AUTOSAR XML (schema 00046)
standard types defined: boolean, uint8, uint16, uint32, boolean_DataConstr, boolean_CompuMethod
package /PortInterfaces
  7 x sender receiver interface:
    LockCmd
      data LockCmd: type=uint8
    LockReq
      data LockReq: type=uint8
    VehSpd
      data VehSpd: type=uint16
    VehSpdVld
      data VehSpdVld: type=uint8
    FrLeDoorSts
      data FrLeDoorSts: type=uint8
    ReLeDoorSts3
      data ReLeDoorSts4: type=uint8
    ReLeDoorSts
      data ReLeDoorSts: type=uint8
  client server interface SetDoorCmd
    operation DoorMethod
      arg outvalue: type=uint8, direction=OUT, server-argument-impl-policy=USE-ARGUMENT-TYPE
      arg invalue: type=uint8, direction=IN, server-argument-impl-policy=USE-ARGUMENT-TYPE
  client server interface SetSeatCmd
    operation SeatMethod
      arg outvalue: type=uint8, direction=OUT, server-argument-impl-policy=USE-ARGUMENT-TYPE
      arg invalue: type=uint8, direction=IN, server-argument-impl-policy=USE-ARGUMENT-TYPE
  client server interface CSwindowCmd
    operation method1
      arg outvalue: type=uint8, direction=OUT, server-argument-impl-policy=USE-ARGUMENT-TYPE
      arg invalue: type=uint8, direction=IN, server-argument-impl-policy=USE-ARGUMENT-TYPE
    operation method2
      arg outvalue: type=uint8, direction=OUT, server-argument-impl-policy=USE-ARGUMENT-TYPE
      arg invalue: type=uint8, direction=IN, server-argument-impl-policy=USE-ARGUMENT-TYPE
package /Constants
  7 x constant specification, all with value-spec=0:
    LockCmd_IV
    LockReq_IV
    VehSpd_IV
    VehSpdVld_IV
    FrLeDoorSts_IV
    ReLeDoorSts4_IV
    ReLeDoorSts_IV
package /ComponentTypes
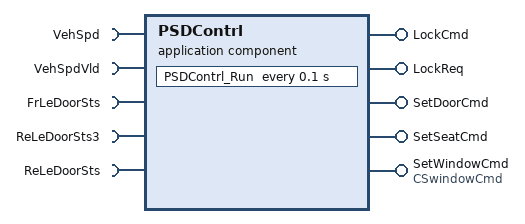
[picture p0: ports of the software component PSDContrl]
  application sw component type PSDContrl
    provide port LockCmd: nonqueued-sender-com-spec{data-element=LockCmd, init-value=constant-reference=LockCmd_IV}, provided-interface=LockCmd
    provide port LockReq: nonqueued-sender-com-spec{data-element=LockReq, init-value=constant-reference=LockReq_IV}, provided-interface=LockReq
    5 x require port:
      VehSpd: nonqueued-receiver-com-spec{data-element=VehSpd, init-value=constant-reference=VehSpd_IV}, required-interface=VehSpd
      VehSpdVld: nonqueued-receiver-com-spec{data-element=VehSpdVld, init-value=constant-reference=VehSpdVld_IV}, required-interface=VehSpdVld
      FrLeDoorSts: nonqueued-receiver-com-spec{data-element=FrLeDoorSts, init-value=constant-reference=FrLeDoorSts_IV}, required-interface=FrLeDoorSts
      ReLeDoorSts3: nonqueued-receiver-com-spec{data-element=ReLeDoorSts4, init-value=constant-reference=ReLeDoorSts4_IV}, required-interface=ReLeDoorSts3
      ReLeDoorSts: nonqueued-receiver-com-spec{data-element=ReLeDoorSts, init-value=constant-reference=ReLeDoorSts_IV}, required-interface=ReLeDoorSts
    provide port SetDoorCmd: server-com-spec=DoorMethod, provided-interface=SetDoorCmd
    provide port SetSeatCmd: server-com-spec=SeatMethod, provided-interface=SetSeatCmd
    provide port SetWindowCmd: provided-com-specs=[method1, method2], provided-interface=CSwindowCmd
    behavior PSDContrl_InternalBehavior
      exclusive area ExampleExclusiveArea
      init event IT_PSDContrl_Init: start-on-event=PSDContrl_Init
      timing event TMT_PSDContrl_Run: start-on-event=PSDContrl_Run, period=0.1
      4 x operation invoked event:
        OIT_PSDContrl_SetDoorCmd_DoorMethod_SetDoorCmd_DoorMethod: start-on-event=PSDContrl_SetDoorCmd_DoorMethod, operation=SetDoorCmd.DoorMethod
        OIT_PSDContrl_SetSeatCmd_SeatMethod_SetSeatCmd_SeatMethod: start-on-event=PSDContrl_SetSeatCmd_SeatMethod, operation=SetSeatCmd.SeatMethod
        OIT_PSDContrl_SetWindowCmd_method1_SetWindowCmd_method1: start-on-event=PSDContrl_SetWindowCmd_method1, operation=SetWindowCmd.method1
        OIT_PSDContrl_SetWindowCmd_method2_SetWindowCmd_method2: start-on-event=PSDContrl_SetWindowCmd_method2, operation=SetWindowCmd.method2
      port-api-options:
        enable-take-address=false, indirect-api=false, port=FrLeDoorSts
        enable-take-address=false, indirect-api=false, port=LockCmd
        enable-take-address=false, indirect-api=false, port=LockReq
        enable-take-address=false, indirect-api=false, port=ReLeDoorSts
        enable-take-address=false, indirect-api=false, port=ReLeDoorSts3
        enable-take-address=false, indirect-api=false, port=SetDoorCmd
        enable-take-address=false, indirect-api=false, port=SetSeatCmd
        enable-take-address=false, indirect-api=false, port=SetWindowCmd
        enable-take-address=false, indirect-api=false, port=VehSpd
        enable-take-address=false, indirect-api=false, port=VehSpdVld
      6 x runnable:
        PSDContrl_Init
        PSDContrl_Run
          data-receive-point-by-arguments:
            5 x access:
              REC_VehSpd_VehSpd: accessed-variable=VehSpd.VehSpd
              REC_VehSpdVld_VehSpdVld: accessed-variable=VehSpdVld.VehSpdVld
              REC_FrLeDoorSts_FrLeDoorSts: accessed-variable=FrLeDoorSts.FrLeDoorSts
              REC_ReLeDoorSts3_ReLeDoorSts4: accessed-variable=ReLeDoorSts3.ReLeDoorSts4
              REC_ReLeDoorSts_ReLeDoorSts: accessed-variable=ReLeDoorSts.ReLeDoorSts
          data-send-points:
            access SEND_LockCmd_LockCmd: accessed-variable=LockCmd.LockCmd
            access SEND_LockReq_LockReq: accessed-variable=LockReq.LockReq
        PSDContrl_SetDoorCmd_DoorMethod
        PSDContrl_SetSeatCmd_SeatMethod
        PSDContrl_SetWindowCmd_method1
        PSDContrl_SetWindowCmd_method2
  swc implementation PSDContrl_Implementation: behavior=PSDContrl_InternalBehavior
